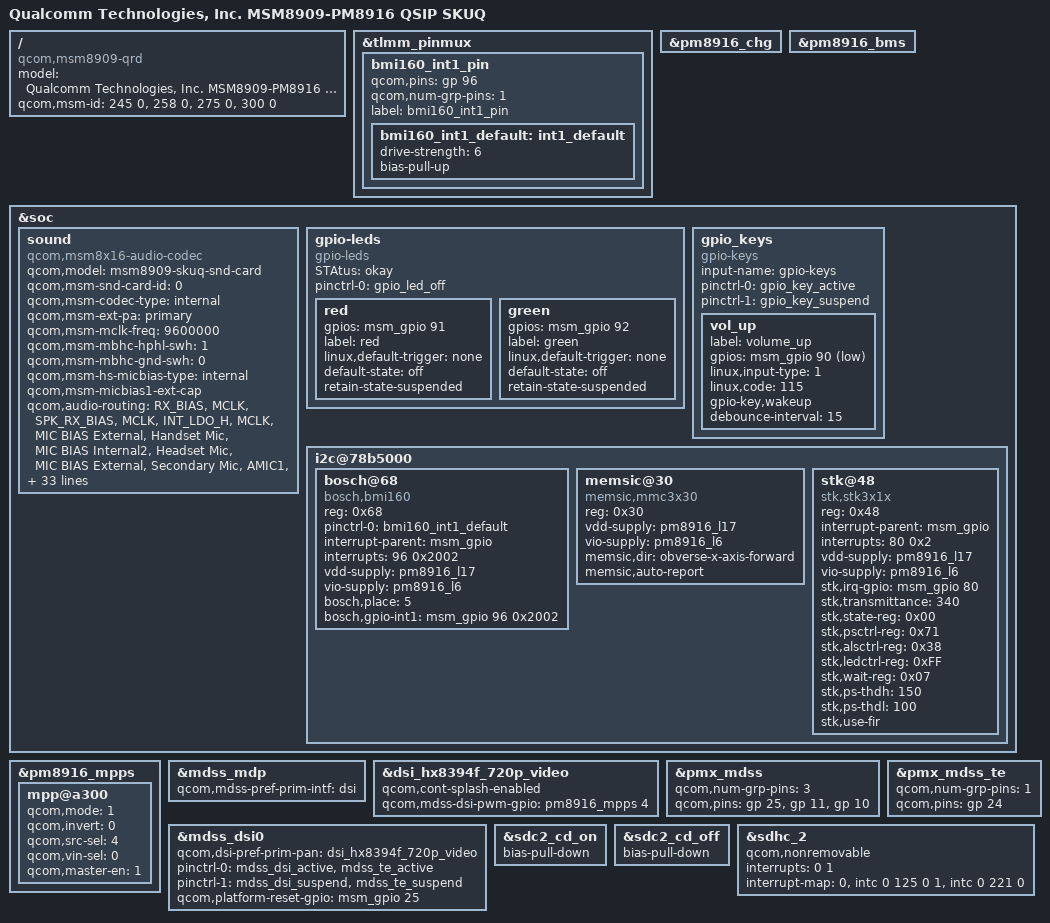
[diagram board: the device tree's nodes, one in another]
/*
 * Copyright (c) 2016, The Linux Foundation. All rights reserved.
 *
 * This program is free software; you can redistribute it and/or modify
 * it under the terms of the GNU General Public License version 2 and
 * only version 2 as published by the Free Software Foundation.
 *
 * This program is distributed in the hope that it will be useful,
 * but WITHOUT ANY WARRANTY; without even the implied warranty of
 * MERCHANTABILITY or FITNESS FOR A PARTICULAR PURPOSE.  See the
 * GNU General Public License for more details.
 */

#include "msm8909-pm8916-qrd.dtsi"
#include "msm8909-camera-sensor-skuq.dtsi"
/ {
	model = "Qualcomm Technologies, Inc. MSM8909-PM8916 QSIP SKUQ";
	compatible = "qcom,msm8909-qrd", "qcom,msm8909", "qcom,qrd";
	qcom,msm-id =   <245 0>,
			<258 0>,
			<275 0>,
			<300 0>;
};

&tlmm_pinmux {
	bmi160_int1_pin {
		qcom,pins = <&gp 96>;
		qcom,num-grp-pins = <1>;
		label = "bmi160_int1_pin";
		bmi160_int1_default: int1_default {
			drive-strength = <6>;
			bias-pull-up;
		};
	};

};

&pm8916_chg {
	status = "ok";
};

&pm8916_bms {
	status = "ok";
};

&soc {
	sound {
		compatible = "qcom,msm8x16-audio-codec";
		qcom,model = "msm8909-skuq-snd-card";
		qcom,msm-snd-card-id = <0>;
		qcom,msm-codec-type = "internal";
		qcom,msm-ext-pa = "primary";
		qcom,msm-mclk-freq = <9600000>;
		qcom,msm-mbhc-hphl-swh = <1>;
		qcom,msm-mbhc-gnd-swh = <0>;
		qcom,msm-hs-micbias-type = "internal";
		qcom,msm-micbias1-ext-cap;
		qcom,audio-routing =
			"RX_BIAS", "MCLK",
			"SPK_RX_BIAS", "MCLK",
			"INT_LDO_H", "MCLK",
			"MIC BIAS External", "Handset Mic",
			"MIC BIAS Internal2", "Headset Mic",
			"MIC BIAS External", "Secondary Mic",
			"AMIC1", "MIC BIAS External",
			"AMIC2", "MIC BIAS Internal2",
			"AMIC3", "MIC BIAS External";
		pinctrl-names = "cdc_lines_act",
				"cdc_lines_sus";
		pinctrl-0 = <&cdc_pdm_lines_act>;
		pinctrl-1 = <&cdc_pdm_lines_sus>;
		asoc-platform = <&pcm0>, <&pcm1>, <&voip>, <&voice>,
				<&loopback>, <&compress>, <&hostless>,
				<&afe>, <&lsm>, <&routing>, <&lpa>,
				<&voice_svc>;
		asoc-platform-names = "msm-pcm-dsp.0", "msm-pcm-dsp.1",
				"msm-voip-dsp", "msm-pcm-voice", "msm-pcm-loopback",
				"msm-compress-dsp", "msm-pcm-hostless", "msm-pcm-afe",
				"msm-lsm-client", "msm-pcm-routing", "msm-pcm-lpa",
				"msm-voice-svc";
		asoc-cpu = 	<&dai_pri_auxpcm>, <&dai_mi2s0>, <&dai_mi2s1>, <&dai_mi2s2>,
				<&dai_mi2s3>, <&bt_sco_rx>, <&bt_sco_tx>, <&bt_a2dp_rx>,
				<&int_fm_rx>, <&int_fm_tx>, <&afe_pcm_rx>, <&afe_pcm_tx>,
				<&afe_proxy_rx>, <&afe_proxy_tx>, <&incall_record_rx>,
				<&incall_record_tx>, <&incall_music_rx>, <&incall_music_2_rx>;
		asoc-cpu-names = "msm-dai-q6-auxpcm.1",
				"msm-dai-q6-mi2s.0", "msm-dai-q6-mi2s.1",
				"msm-dai-q6-mi2s.2", "msm-dai-q6-mi2s.3",
				"msm-dai-q6-dev.12288", "msm-dai-q6-dev.12289",
				"msm-dai-q6-dev.12290",
				"msm-dai-q6-dev.12292", "msm-dai-q6-dev.12293",
				"msm-dai-q6-dev.224", "msm-dai-q6-dev.225",
				"msm-dai-q6-dev.241", "msm-dai-q6-dev.240",
				"msm-dai-q6-dev.32771", "msm-dai-q6-dev.32772",
				"msm-dai-q6-dev.32773", "msm-dai-q6-dev.32770";
		asoc-codec = <&stub_codec>, <&pm8916_tombak_dig>;
		asoc-codec-names = "msm-stub-codec.1", "tombak_codec";
	};

	gpio-leds {
		compatible = "gpio-leds";
		STAtus = "okay";
		pinctrl-names = "default";
		pinctrl-0 = <&gpio_led_off>;

		red {
			gpios = <&msm_gpio 91 0>;
			label = "red";
			linux,default-trigger = "none";
			default-state = "off";
			retain-state-suspended;
		};

		green {
			gpios = <&msm_gpio 92 0>;
			label = "green";
			linux,default-trigger = "none";
			default-state = "off";
			retain-state-suspended;
		};
	};

	gpio_keys {
		compatible = "gpio-keys";
		input-name = "gpio-keys";
		pinctrl-names = "tlmm_gpio_key_active","tlmm_gpio_key_suspend";
		pinctrl-0 = <&gpio_key_active>;
		pinctrl-1 = <&gpio_key_suspend>;

		vol_up {
			label = "volume_up";
			gpios = <&msm_gpio 90 0x1>;
			linux,input-type = <1>;
			linux,code = <115>;
			gpio-key,wakeup;
			debounce-interval = <15>;
		};

		/delete-node/ vol_down;
	};

	i2c@78b5000 {
		bosch@68 { /* Accelerometer and gyroscope sensor */
			compatible = "bosch,bmi160";
			reg = <0x68>;
			pinctrl-names = "default";
			pinctrl-0 = <&bmi160_int1_default>;
			interrupt-parent = <&msm_gpio>;
			interrupts = <96 0x2002>;
			vdd-supply = <&pm8916_l17>;
			vio-supply = <&pm8916_l6>;
			bosch,place = <5>;
			bosch,gpio-int1 = <&msm_gpio 96 0x2002>;
		};

		memsic@30 { /* Magnetic field sensor */
			compatible = "memsic,mmc3x30";
			reg = <0x30>;
			vdd-supply = <&pm8916_l17>;
			vio-supply = <&pm8916_l6>;
			memsic,dir = "obverse-x-axis-forward";
			memsic,auto-report;
		};

		stk@48 {
			compatible = "stk,stk3x1x";
			reg = <0x48>;
			interrupt-parent = <&msm_gpio>;
			interrupts = <80 0x2>;
			vdd-supply = <&pm8916_l17>;
			vio-supply = <&pm8916_l6>;
			stk,irq-gpio = <&msm_gpio 80 0x02>;
			stk,transmittance = <340>;
			stk,state-reg = <0x00>;
			stk,psctrl-reg = <0x71>;
			stk,alsctrl-reg = <0x38>;
			stk,ledctrl-reg = <0xFF>;
			stk,wait-reg = <0x07>;
			stk,ps-thdh = <150>;
			stk,ps-thdl = <100>;
			stk,use-fir;
		};
	};
};

&pm8916_mpps {
	mpp@a300 { /* MPP 4 */
		/* Backlight PWM */
		qcom,mode = <1>;		/* Digital output */
		qcom,invert = <0>;		/* Disable invert */
		qcom,src-sel = <4>;		/* DTEST1 */
		qcom,vin-sel = <0>;		/* VPH_PWR */
		qcom,master-en = <1>;		/* Enable MPP */
	};
};

#include "dsi-panel-hx8394f-720p-video.dtsi"

&mdss_mdp {
	qcom,mdss-pref-prim-intf = "dsi";
};

&dsi_hx8394f_720p_video {
	qcom,cont-splash-enabled;
	qcom,mdss-dsi-pwm-gpio = <&pm8916_mpps 4 0>;
};

&pmx_mdss {
	qcom,num-grp-pins = <3>;
	qcom,pins = <&gp 25>, <&gp 11>, <&gp 10>;
};

&pmx_mdss_te {
	qcom,num-grp-pins = <1>;
	qcom,pins = <&gp 24>;
};

&mdss_dsi0 {
	qcom,dsi-pref-prim-pan = <&dsi_hx8394f_720p_video>;
	pinctrl-names = "mdss_default", "mdss_sleep";
	pinctrl-0 = <&mdss_dsi_active &mdss_te_active>;
	pinctrl-1 = <&mdss_dsi_suspend &mdss_te_suspend>;

	qcom,platform-reset-gpio = <&msm_gpio 25 0>;
};

&sdc2_cd_on {
	/delete-property/ bias-pull-up;
	bias-pull-down;
};

&sdc2_cd_off {
	/delete-property/ bias-disable;
	bias-pull-down;
};

&sdhc_2 {
	qcom,nonremovable;

	interrupts = <0 1>;
	interrupt-map = <0 &intc 0 125 0
		1 &intc 0 221 0>;
	interrupt-names = "hc_irq", "pwr_irq";
	/delete-property/ cd-gpios;
};
